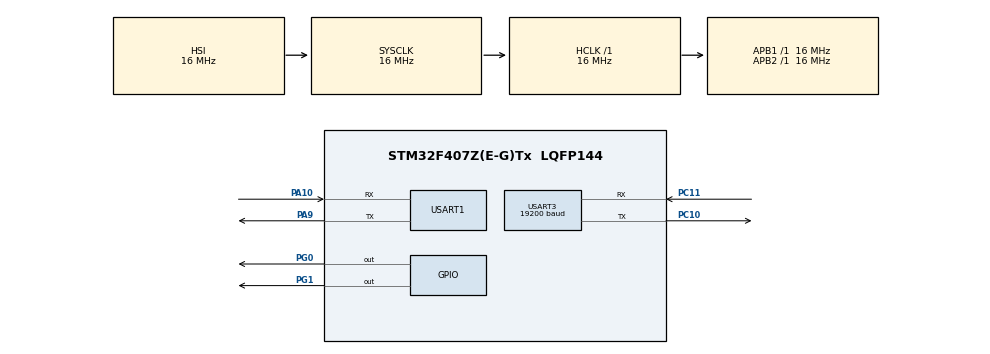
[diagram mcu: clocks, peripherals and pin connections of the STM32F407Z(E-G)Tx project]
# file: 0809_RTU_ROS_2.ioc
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Dma.Request0=USART1_RX
Dma.Request1=USART1_TX
Dma.USART1_RX.0.Direction=DMA_PERIPH_TO_MEMORY
Dma.USART1_RX.0.FIFOMode=DMA_FIFOMODE_DISABLE
Dma.USART1_RX.0.Instance=DMA2_Stream2
Dma.USART1_RX.0.MemDataAlignment=DMA_MDATAALIGN_BYTE
Dma.USART1_RX.0.MemInc=DMA_MINC_ENABLE
Dma.USART1_RX.0.Mode=DMA_NORMAL
Dma.USART1_RX.0.PeriphDataAlignment=DMA_PDATAALIGN_BYTE
Dma.USART1_RX.0.PeriphInc=DMA_PINC_DISABLE
Dma.USART1_RX.0.Priority=DMA_PRIORITY_HIGH
Dma.USART1_TX.1.Direction=DMA_MEMORY_TO_PERIPH
Dma.USART1_TX.1.FIFOMode=DMA_FIFOMODE_DISABLE
Dma.USART1_TX.1.Instance=DMA2_Stream7
Dma.USART1_TX.1.MemDataAlignment=DMA_MDATAALIGN_BYTE
Dma.USART1_TX.1.MemInc=DMA_MINC_ENABLE
Dma.USART1_TX.1.Mode=DMA_NORMAL
Dma.USART1_TX.1.PeriphDataAlignment=DMA_PDATAALIGN_BYTE
Dma.USART1_TX.1.PeriphInc=DMA_PINC_DISABLE
Dma.USART1_TX.1.Priority=DMA_PRIORITY_HIGH
Mcu.Family=STM32F4
Mcu.Name=STM32F407Z(E-G)Tx
Mcu.Package=LQFP144
NVIC.DMA2_Stream2_IRQn=true\:0\:0\:false\:false\:true\:false\:true\:true
NVIC.DMA2_Stream7_IRQn=true\:0\:0\:false\:false\:true\:false\:true\:true
NVIC.PriorityGroup=NVIC_PRIORITYGROUP_4
NVIC.TIM2_IRQn=true\:0\:0\:false\:false\:true\:true\:true\:true
NVIC.USART1_IRQn=true\:0\:0\:false\:false\:true\:true\:true\:true
NVIC.USART3_IRQn=true\:0\:0\:false\:false\:true\:true\:true\:true
PA10.Mode=Asynchronous
PA10.Signal=USART1_RX
PA13.Mode=Serial_Wire
PA13.Signal=SYS_JTMS-SWDIO
PA14.Mode=Serial_Wire
PA14.Signal=SYS_JTCK-SWCLK
PA9.Mode=Asynchronous
PA9.Signal=USART1_TX
PC10.Mode=Asynchronous
PC10.Signal=USART3_TX
PC11.Mode=Asynchronous
PC11.Signal=USART3_RX
PG0.Signal=GPIO_Output
PG1.Signal=GPIO_Output
ProjectManager.HeapSize=0x200
ProjectManager.StackSize=0x400
ProjectManager.TargetToolchain=STM32CubeIDE
RCC.AHBFreq_Value=16000000
RCC.APB1Freq_Value=16000000
RCC.APB2Freq_Value=16000000
RCC.CortexFreq_Value=16000000
RCC.HSE_VALUE=25000000
RCC.HSI_VALUE=16000000
RCC.LSE_VALUE=32768
RCC.SYSCLKFreq_VALUE=16000000
RCC.VCOOutputFreq_Value=192000000
TIM2.Period=49
TIM2.Prescaler=83
USART1.VirtualMode=VM_ASYNC
USART3.BaudRate=19200
USART3.VirtualMode=VM_ASYNC
VP_TIM2_VS_ClockSourceINT.Mode=Internal
board=custom

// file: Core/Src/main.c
/* USER CODE BEGIN Header */
/**
  ******************************************************************************
  * @file           : main.c
  * @brief          : Main program body
  ******************************************************************************
  * @attention
  *
  * Copyright (c) 2022 STMicroelectronics.
  * All rights reserved.
  *
  * This software is licensed under terms that can be found in the LICENSE file
  * in the root directory of this software component.
  * If no LICENSE file comes with this software, it is provided AS-IS.
  *
  ******************************************************************************
  */
/* USER CODE END Header */
#include "main.h"

/* USER CODE BEGIN Includes */
#include "mb.h"
#include "mbport.h"
#include "user_mb_app_m.h"
#include "mb_m.h"

//#include "ros.h"

/* USER CODE END Includes */

TIM_HandleTypeDef htim2;

UART_HandleTypeDef huart1;
UART_HandleTypeDef huart3;
DMA_HandleTypeDef hdma_usart1_rx;
DMA_HandleTypeDef hdma_usart1_tx;

void SystemClock_Config(void);
static void MX_GPIO_Init(void);
static void MX_DMA_Init(void);
static void MX_USART1_UART_Init(void);
static void MX_USART3_UART_Init(void);
static void MX_TIM2_Init(void);

int main(void)
{

  /* MCU Configuration--------------------------------------------------------*/

  /* Reset of all peripherals, Initializes the Flash interface and the Systick. */
  HAL_Init();

  /* Configure the system clock */
  SystemClock_Config();

  /* Initialize all configured peripherals */
  MX_GPIO_Init();
  MX_DMA_Init();
  MX_USART1_UART_Init();
  MX_USART3_UART_Init();
  MX_TIM2_Init();
  /* USER CODE BEGIN 2 */
  eMBMasterInit( MB_RTU, &huart3, 19200, &htim2);
  eMBMasterEnable( );
  setup();
  /* USER CODE END 2 */

  /* Infinite loop */
  /* USER CODE BEGIN WHILE */
  while (1)
  {
	  loop();
    /* USER CODE END WHILE */

  }
}

void SystemClock_Config(void)
{
  RCC_OscInitTypeDef RCC_OscInitStruct = {0};
  RCC_ClkInitTypeDef RCC_ClkInitStruct = {0};

  /** Configure the main internal regulator output voltage
  */
  __HAL_RCC_PWR_CLK_ENABLE();
  __HAL_PWR_VOLTAGESCALING_CONFIG(PWR_REGULATOR_VOLTAGE_SCALE1);

  /** Initializes the RCC Oscillators according to the specified parameters
  * in the RCC_OscInitTypeDef structure.
  */
  RCC_OscInitStruct.OscillatorType = RCC_OSCILLATORTYPE_HSI;
  RCC_OscInitStruct.HSIState = RCC_HSI_ON;
  RCC_OscInitStruct.HSICalibrationValue = RCC_HSICALIBRATION_DEFAULT;
  RCC_OscInitStruct.PLL.PLLState = RCC_PLL_NONE;
  if (HAL_RCC_OscConfig(&RCC_OscInitStruct) != HAL_OK)
  {
    Error_Handler();
  }

  /** Initializes the CPU, AHB and APB buses clocks
  */
  RCC_ClkInitStruct.ClockType = RCC_CLOCKTYPE_HCLK|RCC_CLOCKTYPE_SYSCLK
                              |RCC_CLOCKTYPE_PCLK1|RCC_CLOCKTYPE_PCLK2;
  RCC_ClkInitStruct.SYSCLKSource = RCC_SYSCLKSOURCE_HSI;
  RCC_ClkInitStruct.AHBCLKDivider = RCC_SYSCLK_DIV1;
  RCC_ClkInitStruct.APB1CLKDivider = RCC_HCLK_DIV1;
  RCC_ClkInitStruct.APB2CLKDivider = RCC_HCLK_DIV1;

  if (HAL_RCC_ClockConfig(&RCC_ClkInitStruct, FLASH_LATENCY_0) != HAL_OK)
  {
    Error_Handler();
  }
}

static void MX_TIM2_Init(void)
{

  TIM_ClockConfigTypeDef sClockSourceConfig = {0};
  TIM_MasterConfigTypeDef sMasterConfig = {0};

  htim2.Instance = TIM2;
  htim2.Init.Prescaler = 83;
  htim2.Init.CounterMode = TIM_COUNTERMODE_UP;
  htim2.Init.Period = 49;
  htim2.Init.ClockDivision = TIM_CLOCKDIVISION_DIV1;
  htim2.Init.AutoReloadPreload = TIM_AUTORELOAD_PRELOAD_DISABLE;
  if (HAL_TIM_Base_Init(&htim2) != HAL_OK)
  {
    Error_Handler();
  }
  sClockSourceConfig.ClockSource = TIM_CLOCKSOURCE_INTERNAL;
  if (HAL_TIM_ConfigClockSource(&htim2, &sClockSourceConfig) != HAL_OK)
  {
    Error_Handler();
  }
  sMasterConfig.MasterOutputTrigger = TIM_TRGO_RESET;
  sMasterConfig.MasterSlaveMode = TIM_MASTERSLAVEMODE_DISABLE;
  if (HAL_TIMEx_MasterConfigSynchronization(&htim2, &sMasterConfig) != HAL_OK)
  {
    Error_Handler();
  }

}

static void MX_USART1_UART_Init(void)
{

  huart1.Instance = USART1;
  huart1.Init.BaudRate = 115200;
  huart1.Init.WordLength = UART_WORDLENGTH_8B;
  huart1.Init.StopBits = UART_STOPBITS_1;
  huart1.Init.Parity = UART_PARITY_NONE;
  huart1.Init.Mode = UART_MODE_TX_RX;
  huart1.Init.HwFlowCtl = UART_HWCONTROL_NONE;
  huart1.Init.OverSampling = UART_OVERSAMPLING_16;
  if (HAL_UART_Init(&huart1) != HAL_OK)
  {
    Error_Handler();
  }

}

static void MX_USART3_UART_Init(void)
{

  huart3.Instance = USART3;
  huart3.Init.BaudRate = 19200;
  huart3.Init.WordLength = UART_WORDLENGTH_8B;
  huart3.Init.StopBits = UART_STOPBITS_1;
  huart3.Init.Parity = UART_PARITY_NONE;
  huart3.Init.Mode = UART_MODE_TX_RX;
  huart3.Init.HwFlowCtl = UART_HWCONTROL_NONE;
  huart3.Init.OverSampling = UART_OVERSAMPLING_16;
  if (HAL_UART_Init(&huart3) != HAL_OK)
  {
    Error_Handler();
  }

}

static void MX_DMA_Init(void)
{

  /* DMA controller clock enable */
  __HAL_RCC_DMA2_CLK_ENABLE();

  /* DMA interrupt init */
  /* DMA2_Stream2_IRQn interrupt configuration */
  HAL_NVIC_SetPriority(DMA2_Stream2_IRQn, 0, 0);
  HAL_NVIC_EnableIRQ(DMA2_Stream2_IRQn);
  /* DMA2_Stream7_IRQn interrupt configuration */
  HAL_NVIC_SetPriority(DMA2_Stream7_IRQn, 0, 0);
  HAL_NVIC_EnableIRQ(DMA2_Stream7_IRQn);

}

static void MX_GPIO_Init(void)
{
  GPIO_InitTypeDef GPIO_InitStruct = {0};

  /* GPIO Ports Clock Enable */
  __HAL_RCC_GPIOG_CLK_ENABLE();
  __HAL_RCC_GPIOA_CLK_ENABLE();
  __HAL_RCC_GPIOC_CLK_ENABLE();

  /*Configure GPIO pin Output Level */
  HAL_GPIO_WritePin(GPIOG, GPIO_PIN_0|GPIO_PIN_1, GPIO_PIN_RESET);

  /*Configure GPIO pins : PG0 PG1 */
  GPIO_InitStruct.Pin = GPIO_PIN_0|GPIO_PIN_1;
  GPIO_InitStruct.Mode = GPIO_MODE_OUTPUT_PP;
  GPIO_InitStruct.Pull = GPIO_NOPULL;
  GPIO_InitStruct.Speed = GPIO_SPEED_FREQ_LOW;
  HAL_GPIO_Init(GPIOG, &GPIO_InitStruct);

}

void Error_Handler(void)
{
  __disable_irq();
  while (1)
  {
  }
}
